# earlgrey register map
Vendor: lowRISC; File version: 0.1
CPU: ibex rev01, little endian, no MPU, no FPU, VTOR, 2 interrupt priority bits, 2 interrupts
Registers are 32-bit, read-write, no defined reset value unless marked. A register's access mark holds for its fields unless they carry their own. Offsets are from the block's base; [hi:lo] are bit positions; {n}, {i} and the like mark numbered series.

## LC_CTRL — Manages device life cycle states and transitions, and controls key manager, flash, OTP, and debug access
Base 0x40140000
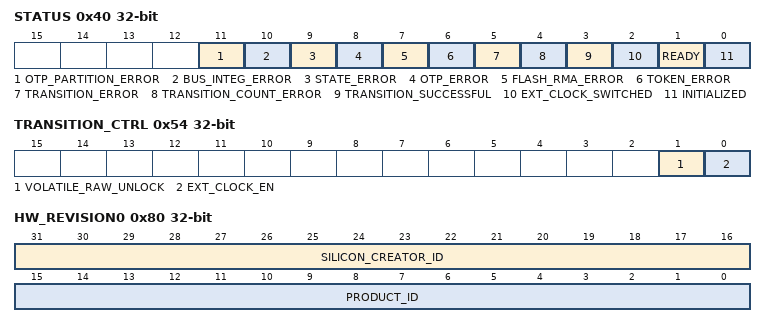
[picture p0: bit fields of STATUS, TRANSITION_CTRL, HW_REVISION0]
0x40 STATUS ro — life cycle status register. Note that all errors are terminal and require a reset cycle.
  [11] OTP_PARTITION_ERROR — This bit is set to 1 if the life cycle partition in OTP is in error state.This bit is intended for production testing during the RAW life cycle state,where the OTP control and status registers are not accessible.This error does not trigger an alert in the life cycle controller.
  [10] BUS_INTEG_ERROR — This bit is set to 1 if a fatal bus integrity fault is detected.This error triggers a fatal_bus_integ_error alert.
  [9] STATE_ERROR — This bit is set to 1 if either the controller FSM state or the life cycle state is invalid orhas been corrupted as part of a tampering attempt. This error will move the life cycle stateautomatically to INVALID and raise a fatal_state_error alert.
  [8] OTP_ERROR — This bit is set to 1 if an error occurred during an OTP programming operation.This error will move the life cycle state automatically to POST_TRANSITION and raise afatal_prog_error alert.
  [7] FLASH_RMA_ERROR — This bit is set to 1 if flash failed to correctly respond to an RMA request.Note that each transition attempt increments the !!LC_TRANSITION_CNT andmoves the life cycle state into POST_TRANSITION.
  [6] TOKEN_ERROR — This bit is set to 1 if the token supplied for a conditional transition was invalid.Note that each transition attempt increments the !!LC_TRANSITION_CNT andmoves the life cycle state into POST_TRANSITION.
  [5] TRANSITION_ERROR — This bit is set to 1 if the last transition command requested an invalid state transition(e.g. DEV -> RAW). Note that each transition attempt increments the !!LC_TRANSITION_CNT andmoves the life cycle state into POST_TRANSITION.
  [4] TRANSITION_COUNT_ERROR — This bit is set to 1 if the !!LC_TRANSITION_CNT has reached its maximum.If this is the case, no more state transitions can be performed.Note that each transition attempt increments the !!LC_TRANSITION_CNT andmoves the life cycle state into POST_TRANSITION.
  [3] TRANSITION_SUCCESSFUL — This bit is set to 1 if the last life cycle transition request was successful.Note that each transition attempt increments the !!LC_TRANSITION_CNT andmoves the life cycle state into POST_TRANSITION.
  [2] EXT_CLOCK_SWITCHED — This bit is set to 1 if the clock manager has successfully switched to the external clock due to!!EXT_CLOCK_EN being set to 1.
  [1] READY — This bit is set to 1 if the life cycle controller has successfully initialized and isready to accept a life cycle transition command.
  [0] INITIALIZED — This bit is set to 1 if the life cycle controller has successfully initialized and thestate exposed in !!LC_STATE and !!LC_TRANSITION_CNT is valid.
0x44 CLAIM_TRANSITION_IF_REGWEN — Register write enable for the hardware mutex register.
  [0] Value — This bit is managed by software and is set to 1 by default.When cleared to 0, the !!CLAIM_TRANSITION_IF mutex register cannot be written to anymore. Write 0 to clear this bit.
0x48 CLAIM_TRANSITION_IF — Hardware mutex to claim exclusive access to the transition interface.
  [7:0] MUTEX — In order to have exclusive access to the transition interface, SW must first claim the associatedhardware mutex by writing kMultiBitBool8True to this register.If the register reads back kMultiBitBool8True, the mutex claim has been successful, and !!TRANSITION_REGWENwill be set automatically to 1 by HW.Write 0 to this register in order to release the HW mutex.
0x4C TRANSITION_REGWEN ro — Register write enable for all transition interface registers.
  [0] Value — This bit is hardware-managed and only readable by software.By default, this bit is set to 0 by hardware.Once SW has claimed the !!CLAIM_TRANSITION_IF mutex, this bit will be set to 1.Note that the life cycle controller sets this bit temporarily to 0 while executing a life cycle statetransition.
0x50 TRANSITION_CMD — Command register for state transition requests.
  [0] START — Writing a 1 to this register initiates the life cycle state transition to the statespecified in !!TRANSITION_TARGET.Note that not all transitions are possible, and certain conditional transitions requirean additional !!TRANSITION_TOKEN_0.In order to have exclusive access to this register, SW must first claim the associatedhardware mutex via !!CLAIM_TRANSITION_IF.
0x54 TRANSITION_CTRL — Control register for state transition requests.
  [1] VOLATILE_RAW_UNLOCK — When set to 1, LC_CTRL performs a volatile lifecycle transition from RAW -> TEST_UNLOCKED0.No state update will be written to OTP, and no reset will be needed after the transition has succeeded.Note that the token to be provided has to be the hashed unlock token, since in this case the token is NOT passed through KMAC before performing the comparison.After a successful VOLATILE_RAW_UNLOCK transition from RAW -> TEST_UNLOCKED0, the LC_CTRL FSM will go back to the IdleSt and set the STATUS.TRANSITION_SUCCESSFUL bit.The LC_CTRL accepts further transition commands in this state.IMPORTANT NOTE: this feature is intended for test chips only in order to mitigate the risks of a malfunctioningOTP macro. Production devices will permanently disable this feature at compile time via the SecVolatileRawUnlockEn parameter.Software can check whether VOLATILE_RAW_UNLOCK is available by writing 1 and reading backthe register value. If the register reads back as 1 the mechanism is available, and if it reads back 0 it is not.
  [0] EXT_CLOCK_EN — When set to 1, the OTP clock will be switched to an externally supplied clock right away when thedevice is in a non-PROD life cycle state. The clock mux will remain switched until the next system reset.
{0x58+4i} TRANSITION_TOKEN_{i} (i=0..3) — 128bit token for conditional transitions.Make sure to set this to 0 for unconditional transitions.Note that this register is shared with the life cycle TAP interface.In order to have exclusive access to this register, SW must first claim the associatedhardware mutex via !!CLAIM_TRANSITION_IF.
  [31:0] Value_{i} — Value
0x68 TRANSITION_TARGET — This register exposes the decoded life cycle state.
  [29:0] STATE — This field encodes the target life cycle state in a redundant enum format.The 5bit state enum is repeated 6x so that it fills the entire 32bit register.The encoding is straightforward replication: [val, val, val, val, val, val].Note that this register is shared with the life cycle TAP interface.In order to have exclusive access to this register, SW must first claim the associatedhardware mutex via !!CLAIM_TRANSITION_IF.
0x6C OTP_VENDOR_TEST_CTRL — Test/vendor-specific settings for the OTP macro wrapper.These values are only active during RAW, TEST_* and RMA life cycle states.In all other states, these values will be gated to zero before sendingthem to the OTP macro wrapper - even if this register is programmed to a non-zero value.
  [31:0] Value
0x70 OTP_VENDOR_TEST_STATUS ro — Test/vendor-specific settings for the OTP macro wrapper.These values are only active during RAW, TEST_* and RMA life cycle states.In all other states, these values will read as zero.
  [31:0] Value
0x74 LC_STATE ro — This register exposes the decoded life cycle state.
  [29:0] STATE — This field exposes the decoded life cycle state in a redundant enum format.The 5bit state enum is repeated 6x so that it fills the entire 32bit register.The encoding is straightforward replication: [val, val, val, val, val, val].
0x78 LC_TRANSITION_CNT ro — This register exposes the state of the decoded life cycle transition counter.
  [4:0] CNT — Number of total life cycle state transition attempts.The life cycle controller allows up to 24 transition attempts.If this counter is equal to 24, the !!LC_STATE is consideredto be invalid and will read as SCRAP.If the counter state is invalid, or the life cycle controller is in the post-transition state,the counter will have the value 31 (i.e., all counter bits will be set).
0x7C LC_ID_STATE ro — This register exposes the id state of the device.
  [31:0] STATE — This field exposes the id state in redundant enum format.The 2bit id state enum is repeated 16x so that it fills the entire 32bit register.The encoding is straightforward replication: [val, val, ... val]."
0x80 HW_REVISION0 ro — This register holds the SILICON_CREATOR_ID and the PRODUCT_ID.
  [31:16] SILICON_CREATOR_ID — ID of the silicon creator.Assigned by the OpenTitan project.Zero is an invalid value.The encoding must follow the following range constraints:0x0000: invalid value0x0001 - 0x3FFF: reserved for use in the open-source OpenTitan project0x4000 - 0x7FFF: reserved for real integrations of OpenTitan0x8000 - 0xFFFF: reserved for future use
  [15:0] PRODUCT_ID — Used to identify a class of devices.Assigned by the Silicon Creator.Zero is an invalid value.The encoding must follow the following range constraints:0x0000: invalid value0x0001 - 0x3FFF: reserved for discrete chip products0x4000 - 0x7FFF: reserved for integrated IP products0x8000 - 0xFFFF: reserved for future use
0x84 HW_REVISION1 ro — This register holds the REVISION_ID.
  [7:0] REVISION_ID — Product revision ID. Assigned by the Silicon Creator.The encoding is not specified other than that different tapeouts must be assigned different revision numbers.I.e., each base or metal layer respin must be reflected so that software can rely on it to modify firmware and driver behavior.Zero is an invalid value.
{0x88+4i} DEVICE_ID_{i} ro (i=0..7) — This is the 256bit DEVICE_ID value that is stored in the HW_CFG partition in OTP.If this register reads all-one, the HW_CFG partition has not been initialized yet or is in error state.If this register reads all-zero, this is indicative that the value has not been programmed to OTP yet.
  [31:0] Value_{i} — Value
{0xA8+4i} MANUF_STATE_{i} ro (i=0..7) — This is a 256bit field used for keeping track of the manufacturing state.
  [31:0] Value_{i} — Value
